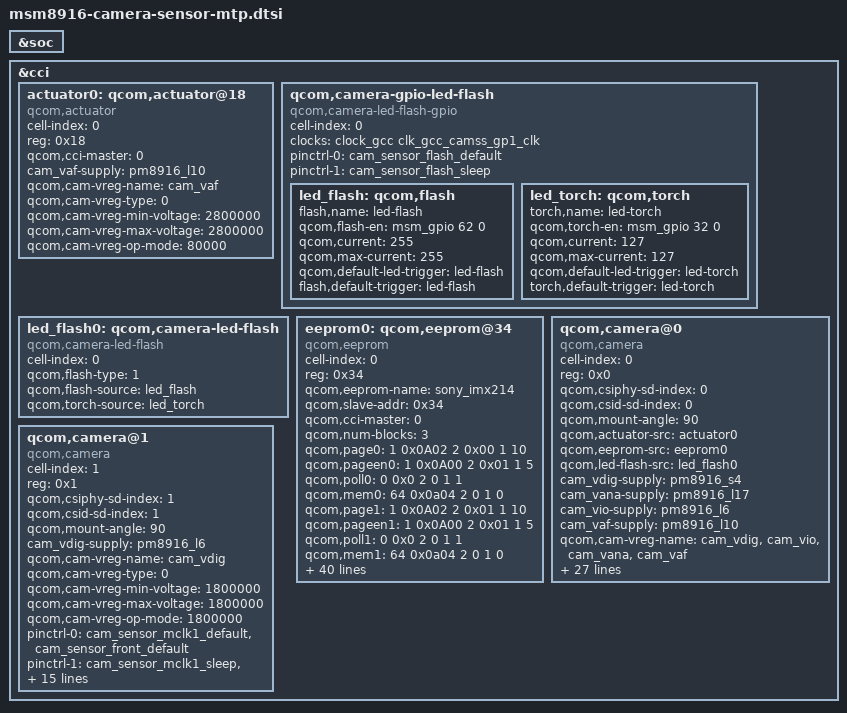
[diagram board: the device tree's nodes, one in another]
/*
 * Copyright (c) 2014, The Linux Foundation. All rights reserved.
 *
 * This program is free software; you can redistribute it and/or modify
 * it under the terms of the GNU General Public License version 2 and
 * only version 2 as published by the Free Software Foundation.
 *
 * This program is distributed in the hope that it will be useful,
 * but WITHOUT ANY WARRANTY; without even the implied warranty of
 * MERCHANTABILITY or FITNESS FOR A PARTICULAR PURPOSE.  See the
 * GNU General Public License for more details.
 */

&soc {
};

&cci {

	actuator0: qcom,actuator@18 {
		cell-index = <0>;
		reg = <0x18>;
		compatible = "qcom,actuator";
		qcom,cci-master = <0>;
		cam_vaf-supply = <&pm8916_l10>;
		qcom,cam-vreg-name = "cam_vaf";
		qcom,cam-vreg-type = <0>;
		qcom,cam-vreg-min-voltage = <2800000>;
		qcom,cam-vreg-max-voltage = <2800000>;
		qcom,cam-vreg-op-mode = <80000>;
	};

	qcom,camera-gpio-led-flash {
		cell-index = <0>;
		compatible = "qcom,camera-led-flash-gpio";
		status = "okay";
 	clocks = <&clock_gcc clk_gcc_camss_gp1_clk>;
		clock-names = "cam_sensor_flash";
		pinctrl-names = "default", "sleep";
		pinctrl-0 = <&cam_sensor_flash_default>;
		pinctrl-1 = <&cam_sensor_flash_sleep>;
		led_flash: qcom,flash {
			flash,name = "led-flash";
			qcom,flash-en = <&msm_gpio 62 0>;
			qcom,current = <255>;
			qcom,max-current = <255>;
            		qcom,default-led-trigger = "led-flash";
			flash,default-trigger = "led-flash";
		};
		led_torch: qcom,torch {
			torch,name = "led-torch";
			qcom,torch-en = <&msm_gpio 32 0>;
			qcom,current = <127>;
			qcom,max-current = <127>;
            		qcom,default-led-trigger = "led-torch";
			torch,default-trigger = "led-torch";
		};
	};

	led_flash0: qcom,camera-led-flash {
		cell-index = <0>;
		compatible = "qcom,camera-led-flash";
		qcom,flash-type = <1>;
		qcom,flash-source = <&led_flash>;
		qcom,torch-source = <&led_torch>;
	};

eeprom0: qcom,eeprom@34 {
		 cell-index = <0>;
		 reg = <0x34>;
		 qcom,eeprom-name = "sony_imx214";
		 compatible = "qcom,eeprom";
		 qcom,slave-addr = <0x34>;
		 qcom,cci-master = <0>;
		 qcom,num-blocks = <3>;

		 qcom,page0 = <1 0x0A02 2 0x00 1 10>;
        	 qcom,pageen0 = <1 0x0A00 2 0x01 1 5>; 
		 qcom,poll0 = <0 0x0 2 0 1 1>;
		 qcom,mem0 = <64 0x0a04 2 0 1 0>;

 		 qcom,page1 = <1 0x0A02 2 0x01 1 10>;
        	 qcom,pageen1 = <1 0x0A00 2 0x01 1 5>; 
		 qcom,poll1 = <0 0x0 2 0 1 1>;
		 qcom,mem1 = <64 0x0a04 2 0 1 0>;

		 qcom,page2 = <1 0x0A02 2 0x02 1 10>;
        	 qcom,pageen2 = <1 0x0A00 2 0x01 1 5>; 
		 qcom,poll2 = <0 0x0 2 0 1 1>;
		 qcom,mem2 = <64 0x0a04 2 0 1 0>;

		cam_vdig-supply = <&pm8916_s4>;
		cam_vana-supply = <&pm8916_l17>;
		cam_vio-supply = <&pm8916_l6>;
		cam_vaf-supply = <&pm8916_l10>;
		 qcom,cam-vreg-name = "cam_vdig", "cam_vio", "cam_vana",
							"cam_vaf";
		qcom,cam-vreg-type = <0 1 0 0>;
		qcom,cam-vreg-min-voltage = <1850000 0 2700000 2800000>;
		qcom,cam-vreg-max-voltage = <1850000 0 2700000 2800000>;
		qcom,cam-vreg-op-mode = <200000 0 80000 100000>;
			pinctrl-names = "cam_default", "cam_suspend";
		pinctrl-0 = <&cam_sensor_mclk0_default
				&cam_sensor_rear_default>;
		pinctrl-1 = <&cam_sensor_mclk0_sleep &cam_sensor_rear_sleep>;
		

		 gpios = <&msm_gpio 26 0>,
			<&msm_gpio 35 0>,
			<&msm_gpio 34 0>,
			<&msm_gpio 109 0>,
			<&msm_gpio 108 0>;
		qcom,gpio-reset = <1>;
		qcom,gpio-standby = <2>;
		qcom,gpio-vdig = <3>;
		qcom,gpio-vana = <4>;
		qcom,gpio-req-tbl-num = <0 1 2 3 4>;
		qcom,gpio-req-tbl-flags = <1 0 0 0 0>;
		qcom,gpio-req-tbl-label = "CAMIF_MCLK",
			"CAM_RESET1",
			"CAM_STANDBY",
			"CAM_GPIO_VDIG",
			"CAM_GPIO_VANA";
			
	 	qcom,cam-power-seq-type = "sensor_gpio","sensor_gpio", "sensor_gpio" , "sensor_clk";
	        qcom,cam-power-seq-val = "sensor_gpio_standby","sensor_gpio_vdig", "sensor_gpio_standby","sensor_cam_mclk";
	        qcom,cam-power-seq-cfg-val = <0 1 1 24000000>;
	        qcom,cam-power-seq-delay = <10 10 10 5>;
 
		
		status = "ok";
        	clocks = <&clock_gcc clk_mclk0_clk_src>,
                	<&clock_gcc clk_gcc_camss_mclk0_clk>;
        	clock-names = "cam_src_clk", "cam_clk"; 

	};
	qcom,camera@0 {
		cell-index = <0>;
		compatible = "qcom,camera";
		reg = <0x0>;
		qcom,csiphy-sd-index = <0>;
		qcom,csid-sd-index = <0>;
		qcom,mount-angle = <90>;
		qcom,actuator-src = <&actuator0>;
		qcom,eeprom-src = <&eeprom0>;
		qcom,led-flash-src = <&led_flash0>;
		
		cam_vdig-supply = <&pm8916_s4>;
		cam_vana-supply = <&pm8916_l17>;
		cam_vio-supply = <&pm8916_l6>;
		cam_vaf-supply = <&pm8916_l10>;
		qcom,cam-vreg-name = "cam_vdig", "cam_vio", "cam_vana",
							"cam_vaf";
		qcom,cam-vreg-type = <0 1 0 0>;
		qcom,cam-vreg-min-voltage = <1850000 0 2700000 2800000>;
		qcom,cam-vreg-max-voltage = <1850000 0 2700000 2800000>;
		qcom,cam-vreg-op-mode = <200000 0 80000 100000>;
		pinctrl-names = "cam_default", "cam_suspend";
		pinctrl-0 = <&cam_sensor_mclk0_default
				&cam_sensor_rear_default>;
		pinctrl-1 = <&cam_sensor_mclk0_sleep &cam_sensor_rear_sleep>;
		gpios = <&msm_gpio 26 0>,
			<&msm_gpio 35 0>,
			<&msm_gpio 34 0>,
			<&msm_gpio 109 0>,
			<&msm_gpio 108 0>;
		qcom,gpio-reset = <1>;
		qcom,gpio-standby = <2>;
		qcom,gpio-vdig = <3>;
		qcom,gpio-vana = <4>;
		qcom,gpio-req-tbl-num = <0 1 2 3 4>;
		qcom,gpio-req-tbl-flags = <1 0 0 0 0>;
		qcom,gpio-req-tbl-label = "CAMIF_MCLK",
			"CAM_RESET1",
			"CAM_STANDBY",
			"CAM_GPIO_VDIG",
			"CAM_GPIO_VANA";
		qcom,sensor-position = <0>;
		qcom,sensor-mode = <0>;
		qcom,cci-master = <0>;
		qcom,mclk-23880000;
		status = "ok";
		clocks = <&clock_gcc clk_mclk0_clk_src>,
				<&clock_gcc clk_gcc_camss_mclk0_clk>;
		clock-names = "cam_src_clk", "cam_clk";
	};

	qcom,camera@1 {
		cell-index = <1>;
		compatible = "qcom,camera";
		reg = <0x1>;
		qcom,csiphy-sd-index = <1>;
		qcom,csid-sd-index = <1>;
		qcom,mount-angle = <90>;
		cam_vdig-supply = <&pm8916_l6>;
		qcom,cam-vreg-name = "cam_vdig";
		qcom,cam-vreg-type = <0>;
		qcom,cam-vreg-min-voltage = <1800000>;
		qcom,cam-vreg-max-voltage = <1800000>;
		qcom,cam-vreg-op-mode = <1800000>;
		pinctrl-names = "cam_default", "cam_suspend";
		pinctrl-0 = <&cam_sensor_mclk1_default &cam_sensor_front_default>;
		pinctrl-1 = <&cam_sensor_mclk1_sleep &cam_sensor_front_sleep>;
		gpios = <&msm_gpio 27 0>,
			<&msm_gpio 28 0>,
			<&msm_gpio 120 0>,
			<&msm_gpio 109 0>,
			<&msm_gpio 108 0>;
		qcom,gpio-reset = <1>;
		qcom,gpio-standby = <2>;
		qcom,gpio-vdig = <3>;
		qcom,gpio-vana = <4>;
		qcom,gpio-req-tbl-num = <0 1 2 3 4>;
		qcom,gpio-req-tbl-flags = <1 0 0 0 0>;
		qcom,gpio-req-tbl-label = "CAMIF_MCLK",
			"CAM_RESET",
			"CAM_STANDBY",
			"CAM_GPIO_VDIG",
			"CAM_GPIO_VANA";
		qcom,cci-master = <0>;
		status = "ok";
		clocks = <&clock_gcc clk_mclk1_clk_src>,
				<&clock_gcc clk_gcc_camss_mclk1_clk>;
		clock-names = "cam_src_clk", "cam_clk";
	};
	
};
